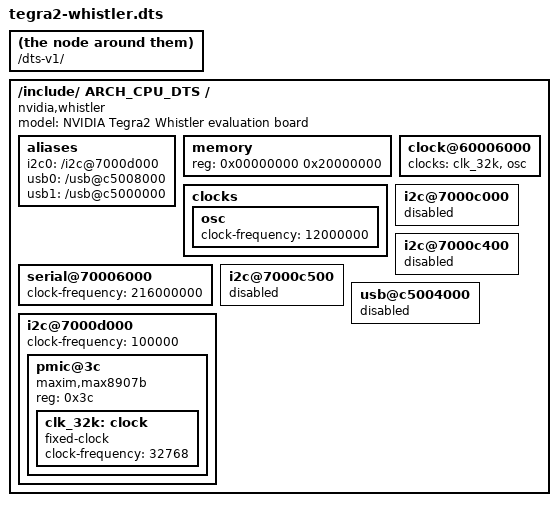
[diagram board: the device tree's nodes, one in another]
/dts-v1/;

/include/ ARCH_CPU_DTS

/ {
	model = "NVIDIA Tegra2 Whistler evaluation board";
	compatible = "nvidia,whistler", "nvidia,tegra20";

	aliases {
		i2c0 = "/i2c@7000d000";
		usb0 = "/usb@c5008000";
		usb1 = "/usb@c5000000";
	};

	memory {
		device_type = "memory";
		reg = < 0x00000000 0x20000000 >;
	};

	clocks {
		osc {
			clock-frequency = <12000000>;
		};
	};

	clock@60006000 {
		clocks = <&clk_32k &osc>;
	};

	serial@70006000 {
		clock-frequency = < 216000000 >;
	};

	i2c@7000c000 {
		status = "disabled";
	};

	i2c@7000c400 {
		status = "disabled";
	};

	i2c@7000c500 {
		status = "disabled";
	};

	i2c@7000d000 {
		clock-frequency = <100000>;

		pmic@3c {
			compatible = "maxim,max8907b";
			reg = <0x3c>;

			clk_32k: clock {
				compatible = "fixed-clock";
				/*
				 * leave out for now due to CPP:
				 * #clock-cells = <0>;
				 */
				clock-frequency = <32768>;
			};
		};
	};

	usb@c5004000 {
		status = "disabled";
	};
};
